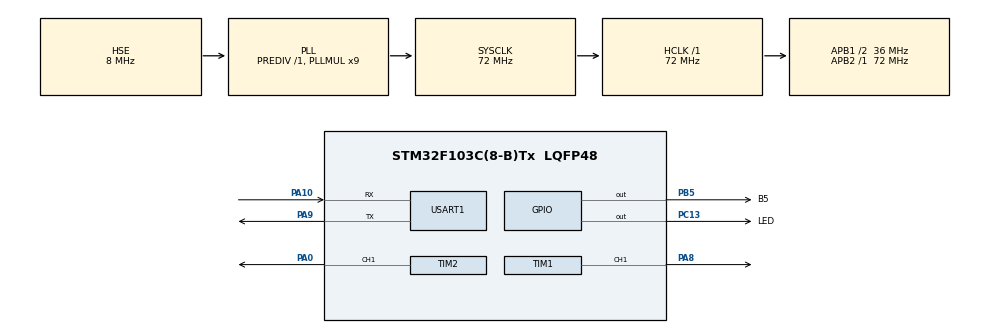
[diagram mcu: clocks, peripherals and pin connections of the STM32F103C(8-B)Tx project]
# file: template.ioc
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Mcu.Family=STM32F1
RCC.PLLSourceVirtual=RCC_PLLSOURCE_HSE
PC15-OSC32_OUT.Mode=LSE-External-Oscillator
Dma.TIM2_CH1.0.MemInc=DMA_MINC_ENABLE
NVIC.DMA1_Channel5_IRQn=true\:0\:0\:false\:false\:true\:false\:true
PD1-OSC_OUT.Mode=HSE-External-Oscillator
TIM2.OCFastMode_PWM-PWM\ Generation1\ CH1=TIM_OCFAST_DISABLE
PA10.Mode=Asynchronous
TIM2.OCMode_PWM-PWM\ Generation1\ CH1=TIM_OCMODE_PWM1
PC13-TAMPER-RTC.Signal=GPIO_Output
Dma.TIM2_CH1.0.Instance=DMA1_Channel5
PD0-OSC_IN.Signal=RCC_OSC_IN
TIM1.Pulse-PWM\ Generation1\ CH1=500
RCC.APB1CLKDivider=RCC_HCLK_DIV2
TIM2.OCPolarity_1=TIM_OCPOLARITY_HIGH
PC14-OSC32_IN.Signal=RCC_OSC32_IN
RCC.SYSCLKSource=RCC_SYSCLKSOURCE_PLLCLK
ProjectManager.StackSize=0x400
PA0-WKUP.Signal=S_TIM2_CH1_ETR
TIM2.Pulse-PWM\ Generation1\ CH1=1000
PD1-OSC_OUT.Signal=RCC_OSC_OUT
PA13.Signal=SYS_JTMS-SWDIO
PA9.Mode=Asynchronous
TIM1.Prescaler=72-1
SH.S_TIM1_CH1.0=TIM1_CH1,PWM Generation1 CH1
ProjectManager.TargetToolchain=Makefile
RCC.HCLKFreq_Value=72000000
RCC.APB2TimFreq_Value=72000000
PA9.Signal=USART1_TX
RCC.USBFreq_Value=72000000
PC15-OSC32_OUT.Signal=RCC_OSC32_OUT
RCC.AHBFreq_Value=72000000
PD0-OSC_IN.Mode=HSE-External-Oscillator
board=custom
PC13-TAMPER-RTC.GPIO_Label=LED
RCC.PLLMUL=RCC_PLL_MUL9
RCC.APB2Freq_Value=72000000
Dma.TIM2_CH1.0.Priority=DMA_PRIORITY_LOW
PC14-OSC32_IN.Mode=LSE-External-Oscillator
PC13-TAMPER-RTC.PinState=GPIO_PIN_SET
VP_TIM2_VS_ClockSourceINT.Mode=Internal
TIM1.Channel-PWM\ Generation1\ CH1=TIM_CHANNEL_1
PA14.Mode=Serial_Wire
PA8.Signal=S_TIM1_CH1
TIM2.Channel-PWM\ Generation1\ CH1=TIM_CHANNEL_1
TIM2.Period=\ 5-1
PA13.Mode=Serial_Wire
Mcu.Name=STM32F103C(8-B)Tx
VP_TIM1_VS_ClockSourceINT.Mode=Internal
RCC.SYSCLKFreq_VALUE=72000000
Mcu.Package=LQFP48
PB5.Signal=GPIO_Output
Dma.TIM2_CH1.0.Mode=DMA_CIRCULAR
TIM2.Prescaler=18-1
USART1.VirtualMode=VM_ASYNC
Dma.TIM2_CH1.0.MemDataAlignment=DMA_MDATAALIGN_HALFWORD
SH.S_TIM2_CH1_ETR.0=TIM2_CH1,PWM Generation1 CH1
PA10.Signal=USART1_RX
PA14.Signal=SYS_JTCK-SWCLK
ProjectManager.HeapSize=0x200
Dma.TIM2_CH1.0.PeriphDataAlignment=DMA_PDATAALIGN_HALFWORD
NVIC.PriorityGroup=NVIC_PRIORITYGROUP_4
PB5.GPIO_Label=B5
RCC.APB1TimFreq_Value=72000000
TIM1.Period=1000-1
Dma.Request0=TIM2_CH1
RCC.APB1Freq_Value=36000000
Dma.TIM2_CH1.0.Direction=DMA_MEMORY_TO_PERIPH
Dma.TIM2_CH1.0.PeriphInc=DMA_PINC_DISABLE

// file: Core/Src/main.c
/* USER CODE BEGIN Header */
/**
  ******************************************************************************
  * @file           : main.c
  * @brief          : Main program body
  ******************************************************************************
  * @attention
  *
  * <h2><center>&copy; Copyright (c) 2021 STMicroelectronics.
  * All rights reserved.</center></h2>
  *
  * This software component is licensed by ST under BSD 3-Clause license,
  * the "License"; You may not use this file except in compliance with the
  * License. You may obtain a copy of the License at:
  *                        opensource.org/licenses/BSD-3-Clause
  *
  ******************************************************************************
  */
/* USER CODE END Header */
#include "main.h"
#include "dma.h"
#include "tim.h"
#include "usart.h"
#include "gpio.h"

/* USER CODE BEGIN Includes */
#include "sk6812.h"
//#include <stdio.h>
/* USER CODE END Includes */

void SystemClock_Config(void);

int main(void)
{

  /* MCU Configuration--------------------------------------------------------*/

  /* Reset of all peripherals, Initializes the Flash interface and the Systick. */
  HAL_Init();

  /* Configure the system clock */
  SystemClock_Config();

  /* Initialize all configured peripherals */
  MX_GPIO_Init();
  MX_DMA_Init();
  MX_USART1_UART_Init();
  MX_TIM2_Init();
  MX_TIM1_Init();
  /* USER CODE BEGIN 2 */
  extern uint16_t send_Buf[NUM];
  SK_CloseAll();
  //HAL_TIM_PWM_Start_DMA(&htim2, TIM_CHANNEL_1, (uint32_t *)send_Buf, NUM);

  // for (size_t i = 0; i < 20; i++)
  // {
  //   send_Buf2[i]=200;
  // }
  //SK_CloseAll();
//     SK_WritePixel(18,255,0,0);
//     SK_WritePixel(19,255,0,0);
// SK_WritePixel(17,255,0,0);

  //__HAL_TIM_SET_COMPARE(&htim1,TIM_CHANNEL_1,800);

  //HAL_TIM_PWM_Start(&htim1, TIM_CHANNEL_1);
  //SK_WritePixel(3,100,0,0);
  //SK_WritePixel(19,0,100,0);
  //SK_Breathing_RGB();

  /* USER CODE END 2 */

  /* Infinite loop */
  /* USER CODE BEGIN WHILE */
  while (1)
  {
    //HAL_GPIO_TogglePin(LED_GPIO_Port,LED_Pin);

    //HAL_TIM_PWM_Start(&htim2, TIM_CHANNEL_1);
    //HAL_Delay(200)

    //SK_Watering_RGB();
    SK_Rainbow(40);
    HAL_GPIO_TogglePin(LED_GPIO_Port,LED_Pin);
    HAL_Delay(3000);
    //HAL_TIM_PWM_Start_DMA(&htim2, TIM_CHANNEL_1, (uint32_t *)send_Buf2,5);
    //HAL_TIM_PWM_Start_DMA(&htim2, TIM_CHANNEL_1, (uint32_t *)send_Buf, NUM);

  //

  //SK_Breathing_RGB();
    /* USER CODE END WHILE */

  }
}

void SystemClock_Config(void)
{
  RCC_OscInitTypeDef RCC_OscInitStruct = {0};
  RCC_ClkInitTypeDef RCC_ClkInitStruct = {0};

  /** Initializes the RCC Oscillators according to the specified parameters
  * in the RCC_OscInitTypeDef structure.
  */
  RCC_OscInitStruct.OscillatorType = RCC_OSCILLATORTYPE_HSE;
  RCC_OscInitStruct.HSEState = RCC_HSE_ON;
  RCC_OscInitStruct.HSEPredivValue = RCC_HSE_PREDIV_DIV1;
  RCC_OscInitStruct.HSIState = RCC_HSI_ON;
  RCC_OscInitStruct.PLL.PLLState = RCC_PLL_ON;
  RCC_OscInitStruct.PLL.PLLSource = RCC_PLLSOURCE_HSE;
  RCC_OscInitStruct.PLL.PLLMUL = RCC_PLL_MUL9;
  if (HAL_RCC_OscConfig(&RCC_OscInitStruct) != HAL_OK)
  {
    Error_Handler();
  }
  /** Initializes the CPU, AHB and APB buses clocks
  */
  RCC_ClkInitStruct.ClockType = RCC_CLOCKTYPE_HCLK|RCC_CLOCKTYPE_SYSCLK
                              |RCC_CLOCKTYPE_PCLK1|RCC_CLOCKTYPE_PCLK2;
  RCC_ClkInitStruct.SYSCLKSource = RCC_SYSCLKSOURCE_PLLCLK;
  RCC_ClkInitStruct.AHBCLKDivider = RCC_SYSCLK_DIV1;
  RCC_ClkInitStruct.APB1CLKDivider = RCC_HCLK_DIV2;
  RCC_ClkInitStruct.APB2CLKDivider = RCC_HCLK_DIV1;

  if (HAL_RCC_ClockConfig(&RCC_ClkInitStruct, FLASH_LATENCY_2) != HAL_OK)
  {
    Error_Handler();
  }
}

/* USER CODE BEGIN 4 */
void HAL_TIM_PWM_PulseFinishedCallback(TIM_HandleTypeDef *htim)
{
	//HAL_TIM_PWM_Stop_DMA(&htim2, TIM_CHANNEL_1);
}

/* USER CODE END 4 */

void Error_Handler(void)
{
  __disable_irq();
  while (1)
  {
  }
}

/************************ (C) COPYRIGHT STMicroelectronics *****END OF FILE****/
